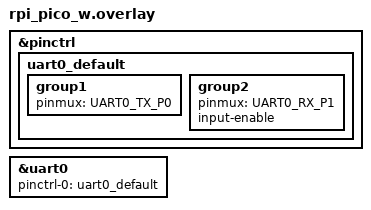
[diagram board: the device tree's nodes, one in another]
  &pinctrl {
    /* configuration for the usart0 "default" state */
    uart0_default: uart0_default {
      /* group 1 */
      group1 {
        /* configure P0 as UART0 TX */
        pinmux = <UART0_TX_P0>;
      };
      /* group 2 */
      group2 {
        /* configure P1 as UART0 RX */
        pinmux = <UART0_RX_P1>;
        /* enable input on pin 1 */
        input-enable;
      };
    };
  };

   #include "rpi_pico_w-pinctrl.dtsi"

   &uart0 {
         pinctrl-0 = <&uart0_default>;
        /* pinctrl-1 = <&uart0_sleep>;*/
        /* pinctrl-names = "default", "sleep";*/
   };
